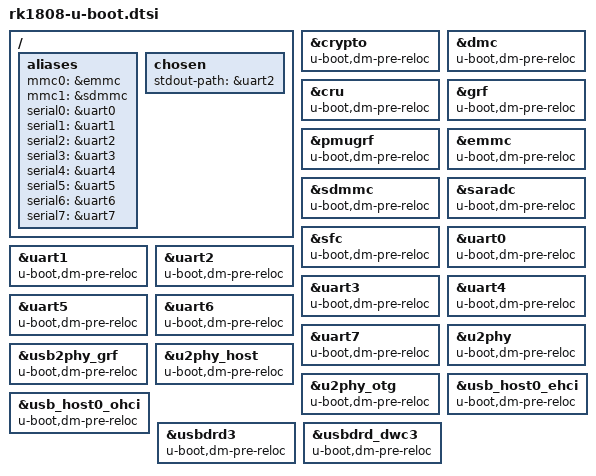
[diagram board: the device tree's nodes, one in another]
// SPDX-License-Identifier:     GPL-2.0+
/*
 * (C) Copyright 2018 Rockchip Electronics Co., Ltd
 *
 */

/ {
	aliases {
		mmc0 = &emmc;
		mmc1 = &sdmmc;

		serial0 = &uart0;
		serial1 = &uart1;
		serial2 = &uart2;
		serial3 = &uart3;
		serial4 = &uart4;
		serial5 = &uart5;
		serial6 = &uart6;
		serial7 = &uart7;
	};

	chosen {
		stdout-path = &uart2;
	};

};

&crypto {
	u-boot,dm-pre-reloc;
};

&dmc {
	u-boot,dm-pre-reloc;
};

&cru {
	u-boot,dm-pre-reloc;
};

&grf {
	u-boot,dm-pre-reloc;
};

&pmugrf {
	u-boot,dm-pre-reloc;
};

&emmc {
	u-boot,dm-pre-reloc;
	status = "okay";
};

&sdmmc {
	u-boot,dm-pre-reloc;
	status = "okay";
};

&saradc {
	u-boot,dm-pre-reloc;
	status = "okay";
};

&sfc {
	u-boot,dm-pre-reloc;
	status = "okay";
};

&uart0 {
	u-boot,dm-pre-reloc;
};

&uart1 {
	u-boot,dm-pre-reloc;
};

&uart2 {
	u-boot,dm-pre-reloc;
};

&uart3 {
	u-boot,dm-pre-reloc;
};

&uart4 {
	u-boot,dm-pre-reloc;
};

&uart5 {
	u-boot,dm-pre-reloc;
};

&uart6 {
	u-boot,dm-pre-reloc;
};

&uart7 {
	u-boot,dm-pre-reloc;
};

&u2phy {
	u-boot,dm-pre-reloc;
	status = "okay";
};

&usb2phy_grf {
	u-boot,dm-pre-reloc;
	status = "okay";
};

&u2phy_host {
	u-boot,dm-pre-reloc;
	status = "okay";
};

&u2phy_otg {
	u-boot,dm-pre-reloc;
	status = "okay";
};

&usb_host0_ehci {
	u-boot,dm-pre-reloc;
	status = "okay";
};

&usb_host0_ohci {
	u-boot,dm-pre-reloc;
	status = "okay";
};

&usbdrd3 {
	u-boot,dm-pre-reloc;
	status = "okay";
};

&usbdrd_dwc3 {
	u-boot,dm-pre-reloc;
	status = "okay";
};
